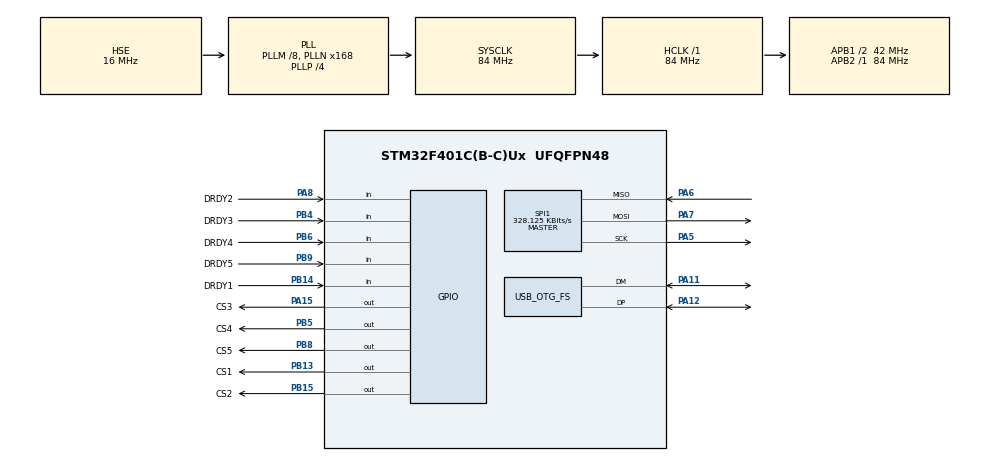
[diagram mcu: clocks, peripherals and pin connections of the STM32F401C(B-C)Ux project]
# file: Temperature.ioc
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IWDG.Prescaler=IWDG_PRESCALER_16
IWDG.Reload=4095
Mcu.Family=STM32F4
Mcu.Name=STM32F401C(B-C)Ux
Mcu.Package=UFQFPN48
NVIC.OTG_FS_IRQn=true\:0\:0\:false\:false\:true\:false\:true\:true
NVIC.PriorityGroup=NVIC_PRIORITYGROUP_4
PA11.Mode=Device_Only
PA11.Signal=USB_OTG_FS_DM
PA12.Mode=Device_Only
PA12.Signal=USB_OTG_FS_DP
PA13.Mode=Trace_Asynchronous_SW
PA13.Signal=SYS_JTMS-SWDIO
PA14.Mode=Trace_Asynchronous_SW
PA14.Signal=SYS_JTCK-SWCLK
PA15.GPIO_Label=CS3
PA15.GPIO_Speed=GPIO_SPEED_FREQ_HIGH
PA15.Signal=GPIO_Output
PA5.GPIO_Speed=GPIO_SPEED_FREQ_VERY_HIGH
PA5.Mode=Full_Duplex_Master
PA5.Signal=SPI1_SCK
PA6.GPIO_PuPd=GPIO_NOPULL
PA6.GPIO_Speed=GPIO_SPEED_FREQ_VERY_HIGH
PA6.Mode=Full_Duplex_Master
PA6.Signal=SPI1_MISO
PA7.GPIO_PuPd=GPIO_NOPULL
PA7.GPIO_Speed=GPIO_SPEED_FREQ_VERY_HIGH
PA7.Mode=Full_Duplex_Master
PA7.Signal=SPI1_MOSI
PA8.GPIO_Label=DRDY2
PA8.Signal=GPIO_Input
PB13.GPIO_Label=CS1
PB13.GPIO_Speed=GPIO_SPEED_FREQ_HIGH
PB13.Signal=GPIO_Output
PB14.GPIO_Label=DRDY1
PB14.Signal=GPIO_Input
PB15.GPIO_Label=CS2
PB15.GPIO_Speed=GPIO_SPEED_FREQ_HIGH
PB15.Signal=GPIO_Output
PB3.Mode=Trace_Asynchronous_SW
PB3.Signal=SYS_JTDO-SWO
PB4.GPIO_Label=DRDY3
PB4.Signal=GPIO_Input
PB5.GPIO_Label=CS4
PB5.GPIO_Speed=GPIO_SPEED_FREQ_HIGH
PB5.PinState=GPIO_PIN_RESET
PB5.Signal=GPIO_Output
PB6.GPIO_Label=DRDY4
PB6.Signal=GPIO_Input
PB8.GPIO_Label=CS5
PB8.GPIO_Speed=GPIO_SPEED_FREQ_HIGH
PB8.PinState=GPIO_PIN_RESET
PB8.Signal=GPIO_Output
PB9.GPIO_Label=DRDY5
PB9.Signal=GPIO_Input
PH0\ -\ OSC_IN.Mode=HSE-External-Oscillator
PH0\ -\ OSC_IN.Signal=RCC_OSC_IN
PH1\ -\ OSC_OUT.Mode=HSE-External-Oscillator
PH1\ -\ OSC_OUT.Signal=RCC_OSC_OUT
ProjectManager.HeapSize=0x200
ProjectManager.StackSize=0x400
ProjectManager.TargetToolchain=Makefile
RCC.48MHZClocksFreq_Value=48000000
RCC.AHBFreq_Value=84000000
RCC.APB1CLKDivider=RCC_HCLK_DIV2
RCC.APB1Freq_Value=42000000
RCC.APB1TimFreq_Value=84000000
RCC.APB2Freq_Value=84000000
RCC.APB2TimFreq_Value=84000000
RCC.CortexFreq_Value=84000000
RCC.HCLKFreq_Value=84000000
RCC.HSE_VALUE=16000000
RCC.HSI_VALUE=16000000
RCC.LSE_VALUE=32768
RCC.PLLM=8
RCC.PLLN=168
RCC.PLLP=RCC_PLLP_DIV4
RCC.PLLQ=7
RCC.SYSCLKFreq_VALUE=84000000
RCC.SYSCLKSource=RCC_SYSCLKSOURCE_PLLCLK
RCC.VCOOutputFreq_Value=336000000
SPI1.BaudRatePrescaler=SPI_BAUDRATEPRESCALER_256
SPI1.CLKPhase=SPI_PHASE_2EDGE
SPI1.CalculateBaudRate=328.125 KBits/s
SPI1.Direction=SPI_DIRECTION_2LINES
SPI1.FirstBit=SPI_FIRSTBIT_MSB
SPI1.Mode=SPI_MODE_MASTER
SPI1.VirtualType=VM_MASTER
USB_DEVICE.CLASS_NAME_FS=CDC
USB_DEVICE.VirtualMode=Cdc
USB_DEVICE.VirtualModeFS=Cdc_FS
USB_OTG_FS.VirtualMode=Device_Only
VP_CRC_VS_CRC.Mode=CRC_Activate
VP_IWDG_VS_IWDG.Mode=IWDG_Activate
VP_USB_DEVICE_VS_USB_DEVICE_CDC_FS.Mode=CDC_FS
board=custom

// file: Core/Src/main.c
/* USER CODE BEGIN Header */
/**
  ******************************************************************************
  * @file           : main.c
  * @brief          : Main program body
  ******************************************************************************
  *
  *Temperature Board
  *Temperature
 *ToDo
 * 1. Functioning SPI Comm. - Ready to test.
 * 2. SI7051 Temp.
 * 3. JunctAvg Temp.
 * 4. USB comm and Serial in. - Ready to test.
 *
 * Versions:
 * 1.0	Stable. WIP
  *
  ******************************************************************************
  */
/* USER CODE END Header */
#include "main.h"
#include "usb_device.h"

/* USER CODE BEGIN Includes */
#include "CAProtocolStm.h"
#include "Temperature.h"
/* USER CODE END Includes */

CRC_HandleTypeDef hcrc;

IWDG_HandleTypeDef hiwdg;

SPI_HandleTypeDef hspi1;

void SystemClock_Config(void);
static void MX_GPIO_Init(void);
static void MX_SPI1_Init(void);
static void MX_IWDG_Init(void);
static void MX_CRC_Init(void);

int main(void)
{

  /* MCU Configuration--------------------------------------------------------*/

  /* Reset of all peripherals, Initializes the Flash interface and the Systick. */
  HAL_Init();

  /* Configure the system clock */
  SystemClock_Config();

  /* USER CODE BEGIN SysInit */
  const char *bootMsg = CAonBoot();
  /* USER CODE END SysInit */

  /* Initialize all configured peripherals */
  MX_GPIO_Init();
  MX_USB_DEVICE_Init();
  MX_SPI1_Init();
  MX_IWDG_Init();
  MX_CRC_Init();
  /* USER CODE BEGIN 2 */
  // Disable wwdg until print frequency has stabilised after first run.
  // Enabled again in LoopTemperature.
  InitTemperature(&hspi1, &hcrc, bootMsg);
  /* USER CODE END 2 */

  /* Infinite loop */
  /* USER CODE BEGIN WHILE */
  while (1)
  {
	  // Update the watchdog if the SPI communication to the
	  // ADS1120 chips work as expected.
	  HAL_IWDG_Refresh(&hiwdg);
    LoopTemperature(bootMsg);
    /* USER CODE END WHILE */

  }
}

void SystemClock_Config(void)
{
  RCC_OscInitTypeDef RCC_OscInitStruct = {0};
  RCC_ClkInitTypeDef RCC_ClkInitStruct = {0};

  /** Configure the main internal regulator output voltage
  */
  __HAL_RCC_PWR_CLK_ENABLE();
  __HAL_PWR_VOLTAGESCALING_CONFIG(PWR_REGULATOR_VOLTAGE_SCALE2);

  /** Initializes the RCC Oscillators according to the specified parameters
  * in the RCC_OscInitTypeDef structure.
  */
  RCC_OscInitStruct.OscillatorType = RCC_OSCILLATORTYPE_LSI|RCC_OSCILLATORTYPE_HSE;
  RCC_OscInitStruct.HSEState = RCC_HSE_ON;
  RCC_OscInitStruct.LSIState = RCC_LSI_ON;
  RCC_OscInitStruct.PLL.PLLState = RCC_PLL_ON;
  RCC_OscInitStruct.PLL.PLLSource = RCC_PLLSOURCE_HSE;
  RCC_OscInitStruct.PLL.PLLM = 8;
  RCC_OscInitStruct.PLL.PLLN = 168;
  RCC_OscInitStruct.PLL.PLLP = RCC_PLLP_DIV4;
  RCC_OscInitStruct.PLL.PLLQ = 7;
  if (HAL_RCC_OscConfig(&RCC_OscInitStruct) != HAL_OK)
  {
    Error_Handler();
  }

  /** Initializes the CPU, AHB and APB buses clocks
  */
  RCC_ClkInitStruct.ClockType = RCC_CLOCKTYPE_HCLK|RCC_CLOCKTYPE_SYSCLK
                              |RCC_CLOCKTYPE_PCLK1|RCC_CLOCKTYPE_PCLK2;
  RCC_ClkInitStruct.SYSCLKSource = RCC_SYSCLKSOURCE_PLLCLK;
  RCC_ClkInitStruct.AHBCLKDivider = RCC_SYSCLK_DIV1;
  RCC_ClkInitStruct.APB1CLKDivider = RCC_HCLK_DIV2;
  RCC_ClkInitStruct.APB2CLKDivider = RCC_HCLK_DIV1;

  if (HAL_RCC_ClockConfig(&RCC_ClkInitStruct, FLASH_LATENCY_2) != HAL_OK)
  {
    Error_Handler();
  }
}

static void MX_CRC_Init(void)
{

  hcrc.Instance = CRC;
  if (HAL_CRC_Init(&hcrc) != HAL_OK)
  {
    Error_Handler();
  }

}

static void MX_IWDG_Init(void)
{

  hiwdg.Instance = IWDG;
  hiwdg.Init.Prescaler = IWDG_PRESCALER_16;
  hiwdg.Init.Reload = 4095;
  if (HAL_IWDG_Init(&hiwdg) != HAL_OK)
  {
    Error_Handler();
  }

}

static void MX_SPI1_Init(void)
{

  /* SPI1 parameter configuration*/
  hspi1.Instance = SPI1;
  hspi1.Init.Mode = SPI_MODE_MASTER;
  hspi1.Init.Direction = SPI_DIRECTION_2LINES;
  hspi1.Init.DataSize = SPI_DATASIZE_8BIT;
  hspi1.Init.CLKPolarity = SPI_POLARITY_LOW;
  hspi1.Init.CLKPhase = SPI_PHASE_2EDGE;
  hspi1.Init.NSS = SPI_NSS_SOFT;
  hspi1.Init.BaudRatePrescaler = SPI_BAUDRATEPRESCALER_256;
  hspi1.Init.FirstBit = SPI_FIRSTBIT_MSB;
  hspi1.Init.TIMode = SPI_TIMODE_DISABLE;
  hspi1.Init.CRCCalculation = SPI_CRCCALCULATION_DISABLE;
  hspi1.Init.CRCPolynomial = 10;
  if (HAL_SPI_Init(&hspi1) != HAL_OK)
  {
    Error_Handler();
  }

}

static void MX_GPIO_Init(void)
{
  GPIO_InitTypeDef GPIO_InitStruct = {0};

  /* GPIO Ports Clock Enable */
  __HAL_RCC_GPIOH_CLK_ENABLE();
  __HAL_RCC_GPIOA_CLK_ENABLE();
  __HAL_RCC_GPIOB_CLK_ENABLE();

  /*Configure GPIO pin Output Level */
  HAL_GPIO_WritePin(GPIOB, CS1_Pin|CS2_Pin|CS4_Pin|CS5_Pin, GPIO_PIN_RESET);

  /*Configure GPIO pin Output Level */
  HAL_GPIO_WritePin(CS3_GPIO_Port, CS3_Pin, GPIO_PIN_RESET);

  /*Configure GPIO pins : CS1_Pin CS2_Pin CS4_Pin CS5_Pin */
  GPIO_InitStruct.Pin = CS1_Pin|CS2_Pin|CS4_Pin|CS5_Pin;
  GPIO_InitStruct.Mode = GPIO_MODE_OUTPUT_PP;
  GPIO_InitStruct.Pull = GPIO_NOPULL;
  GPIO_InitStruct.Speed = GPIO_SPEED_FREQ_HIGH;
  HAL_GPIO_Init(GPIOB, &GPIO_InitStruct);

  /*Configure GPIO pins : DRDY1_Pin DRDY3_Pin DRDY4_Pin DRDY5_Pin */
  GPIO_InitStruct.Pin = DRDY1_Pin|DRDY3_Pin|DRDY4_Pin|DRDY5_Pin;
  GPIO_InitStruct.Mode = GPIO_MODE_INPUT;
  GPIO_InitStruct.Pull = GPIO_NOPULL;
  HAL_GPIO_Init(GPIOB, &GPIO_InitStruct);

  /*Configure GPIO pin : DRDY2_Pin */
  GPIO_InitStruct.Pin = DRDY2_Pin;
  GPIO_InitStruct.Mode = GPIO_MODE_INPUT;
  GPIO_InitStruct.Pull = GPIO_NOPULL;
  HAL_GPIO_Init(DRDY2_GPIO_Port, &GPIO_InitStruct);

  /*Configure GPIO pin : CS3_Pin */
  GPIO_InitStruct.Pin = CS3_Pin;
  GPIO_InitStruct.Mode = GPIO_MODE_OUTPUT_PP;
  GPIO_InitStruct.Pull = GPIO_NOPULL;
  GPIO_InitStruct.Speed = GPIO_SPEED_FREQ_HIGH;
  HAL_GPIO_Init(CS3_GPIO_Port, &GPIO_InitStruct);

}

void Error_Handler(void)
{
  __disable_irq();
  while (1)
  {
  }
}
